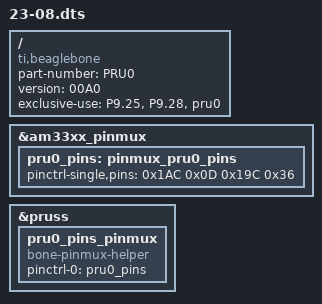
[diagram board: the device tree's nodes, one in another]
/dts-v1/;  
/plugin/;  

/{  
   compatible = "ti,beaglebone", "ti,beaglebone-green", "ti,beaglebone-black";  
   part-number = "PRU0";
   version = "00A0";
   exclusive-use =  
      "P9.25","P9.28","pru0";  
   
   fragment@0 {  
   	target = <&am33xx_pinmux>;  
    	__overlay__ {  
      		pru0_pins: pinmux_pru0_pins {  
      			pinctrl-single,pins = <0x1AC 0x0D 0x19C 0x36>;  
      		};  
    	};  
   };  
     
   fragment@1 {
        target = <&pruss>;
        __overlay__ {
            pru0_pins_pinmux {
                compatible = "bone-pinmux-helper";
                status = "okay";
                pinctrl-names = "default";
                pinctrl-0 = <&pru0_pins>;
            };
        };
   };

};  
  
